# STM32F107xx register map
File version: 1.2
CPU: 
Registers are 32-bit, read-write, reset 0x0 unless marked. A register's access mark holds for its fields unless they carry their own. Offsets are from the block's base; [hi:lo] are bit positions; {n}, {i} and the like mark numbered series.

## CAN2 — Controller area network
Base 0x40006800
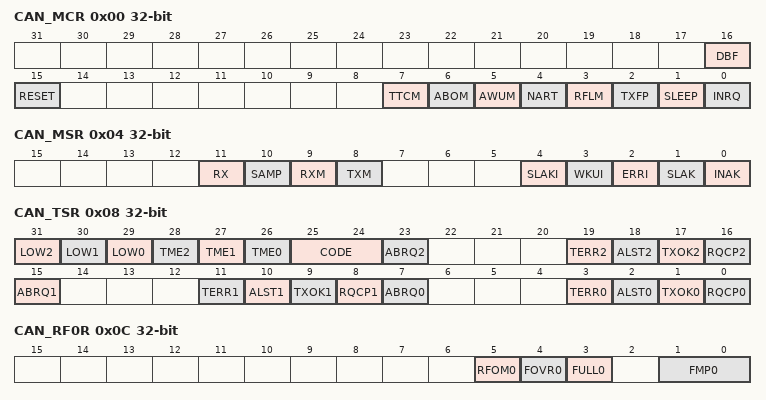
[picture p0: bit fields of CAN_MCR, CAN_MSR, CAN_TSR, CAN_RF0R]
0x00 CAN_MCR
  [16] DBF, [15] RESET, [7] TTCM, [6] ABOM, [5] AWUM, [4] NART, [3] RFLM, [2] TXFP, [1] SLEEP, [0] INRQ
0x04 CAN_MSR access per field
  [11] RX ro, [10] SAMP ro, [9] RXM ro, [8] TXM ro, [4] SLAKI rw, [3] WKUI rw, [2] ERRI rw, [1] SLAK ro, [0] INAK ro
0x08 CAN_TSR access per field
  [31] LOW2 ro — Lowest priority flag for mailbox 2
  [30] LOW1 ro — Lowest priority flag for mailbox 1
  [29] LOW0 ro — Lowest priority flag for mailbox 0
  [28] TME2 ro — Lowest priority flag for mailbox 2
  [27] TME1 ro — Lowest priority flag for mailbox 1
  [26] TME0 ro — Lowest priority flag for mailbox 0
  [25:24] CODE ro
  [23] ABRQ2 rw
  [19] TERR2 rw
  [18] ALST2 rw
  [17] TXOK2 rw
  [16] RQCP2 rw
  [15] ABRQ1 rw
  [11] TERR1 rw
  [10] ALST1 rw
  [9] TXOK1 rw
  [8] RQCP1 rw
  [7] ABRQ0 rw
  [3] TERR0 rw
  [2] ALST0 rw
  [1] TXOK0 rw
  [0] RQCP0 rw
0x0C CAN_RF0R access per field
  [5] RFOM0 rw, [4] FOVR0 rw, [3] FULL0 rw, [1:0] FMP0 ro
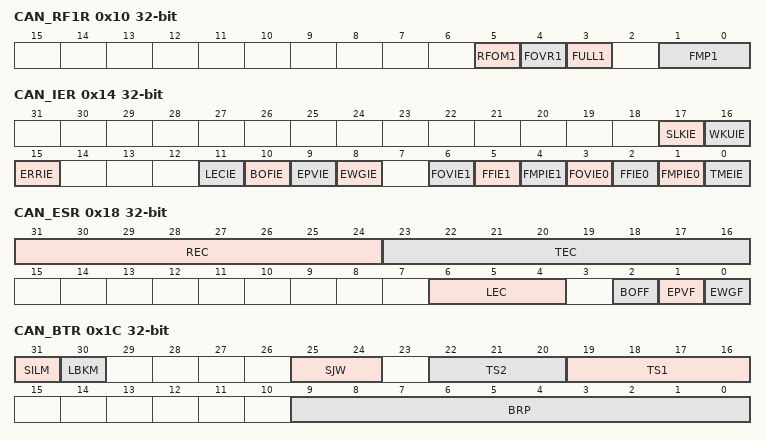
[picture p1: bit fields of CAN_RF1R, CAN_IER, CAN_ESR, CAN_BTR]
0x10 CAN_RF1R access per field
  [5] RFOM1 rw, [4] FOVR1 rw, [3] FULL1 rw, [1:0] FMP1 ro
0x14 CAN_IER
  [17] SLKIE, [16] WKUIE, [15] ERRIE, [11] LECIE, [10] BOFIE, [9] EPVIE, [8] EWGIE, [6] FOVIE1, [5] FFIE1, [4] FMPIE1, [3] FOVIE0, [2] FFIE0, [1] FMPIE0, [0] TMEIE
0x18 CAN_ESR access per field
  [31:24] REC ro, [23:16] TEC ro, [6:4] LEC rw, [2] BOFF ro, [1] EPVF ro, [0] EWGF ro
0x1C CAN_BTR
  [31] SILM, [30] LBKM, [25:24] SJW, [22:20] TS2, [19:16] TS1, [9:0] BRP
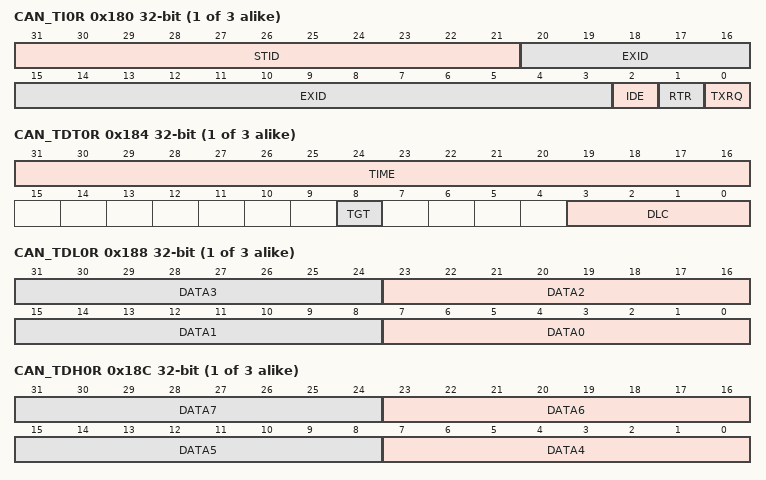
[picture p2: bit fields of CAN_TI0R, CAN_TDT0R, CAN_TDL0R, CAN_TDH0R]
{0x180+0x10*i} CAN_TI{i}R (i=0..2)
  [31:21] STID, [20:3] EXID, [2] IDE, [1] RTR, [0] TXRQ
{0x184+0x10*i} CAN_TDT{i}R (i=0..2)
  [31:16] TIME, [8] TGT, [3:0] DLC
{0x188+0x10*i} CAN_TDL{i}R (i=0..2)
  [8n+7:8n] DATA{n} (n=0..3)
{0x18C+0x10*i} CAN_TDH{i}R (i=0..2)
  [8n-25:8n-32] DATA{n} (n=4..7)
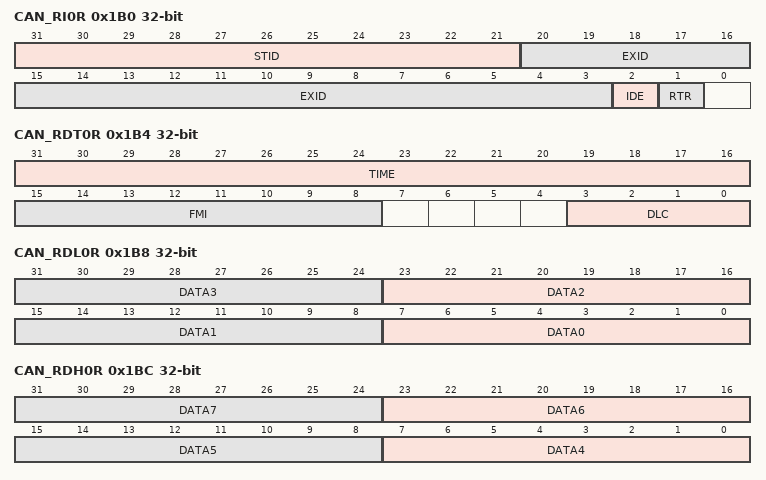
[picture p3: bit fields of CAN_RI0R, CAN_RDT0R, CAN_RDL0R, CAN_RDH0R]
0x1B0 CAN_RI0R ro
  [31:21] STID, [20:3] EXID, [2] IDE, [1] RTR
0x1B4 CAN_RDT0R ro
  [31:16] TIME, [15:8] FMI, [3:0] DLC
0x1B8 CAN_RDL0R ro
  [8n+7:8n] DATA{n} (n=0..3)
0x1BC CAN_RDH0R ro
  [8n-25:8n-32] DATA{n} (n=4..7)
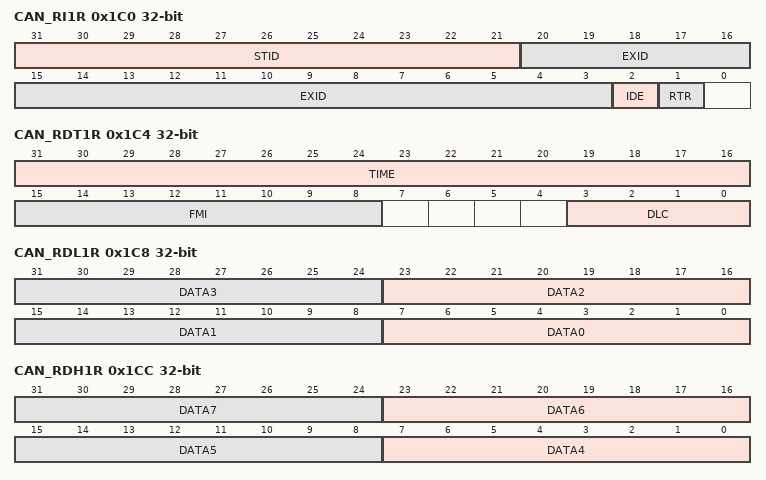
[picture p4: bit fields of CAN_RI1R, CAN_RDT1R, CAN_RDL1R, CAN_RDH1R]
0x1C0 CAN_RI1R ro
  [31:21] STID, [20:3] EXID, [2] IDE, [1] RTR
0x1C4 CAN_RDT1R ro
  [31:16] TIME, [15:8] FMI, [3:0] DLC
0x1C8 CAN_RDL1R ro
  [8n+7:8n] DATA{n} (n=0..3)
0x1CC CAN_RDH1R ro
  [8n-25:8n-32] DATA{n} (n=4..7)
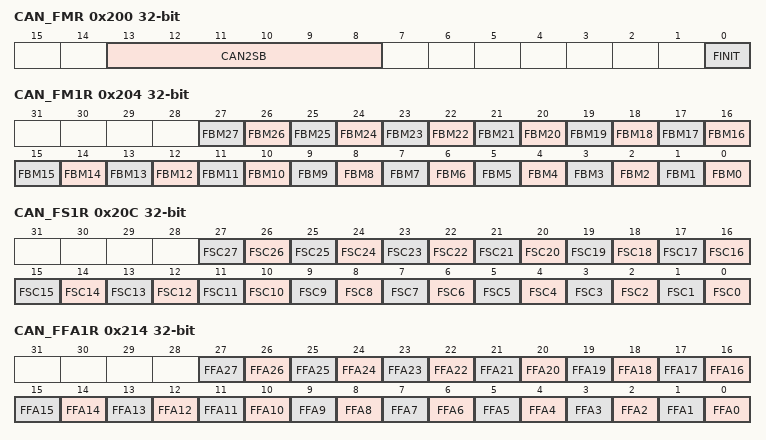
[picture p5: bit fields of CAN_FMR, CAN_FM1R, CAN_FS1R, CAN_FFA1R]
0x200 CAN_FMR
  [13:8] CAN2SB, [0] FINIT
0x204 CAN_FM1R
  [n] FBM{n} (n=0..27) — Filter mode
0x20C CAN_FS1R
  [n] FSC{n} (n=0..27) — Filter scale configuration
0x214 CAN_FFA1R
  [n] FFA{n} (n=0..27) — Filter FIFO assignment for filter {n}
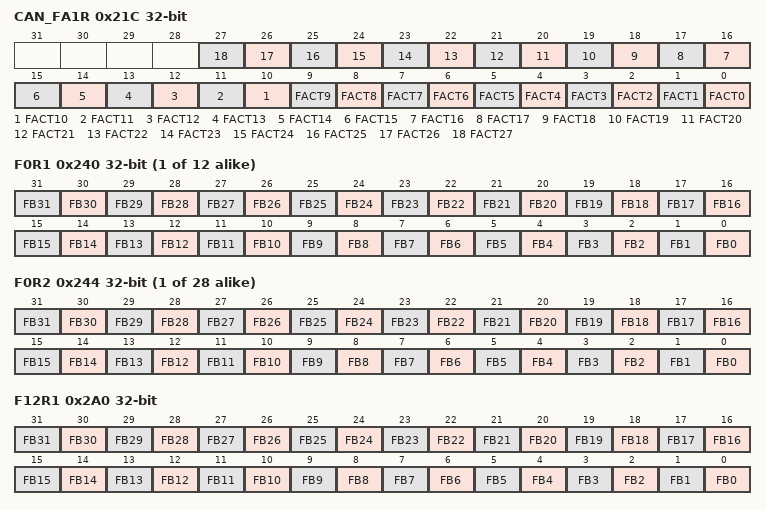
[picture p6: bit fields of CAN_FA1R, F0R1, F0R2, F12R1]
0x21C CAN_FA1R
  [n] FACT{n} (n=0..27) — Filter active
{0x240+8i} F{i}R1 (i=0..11) — Filter bank {i} register 1
  [n] FB{n} (n=0..31) — Filter bits
{0x244+8i} F{i}R2 (i=0..27) — Filter bank {i} register 2
  [n] FB{n} (n=0..31) — Filter bits
0x2A0 F12R1 — Filter bank 4 register 1
  [n] FB{n} (n=0..31) — Filter bits
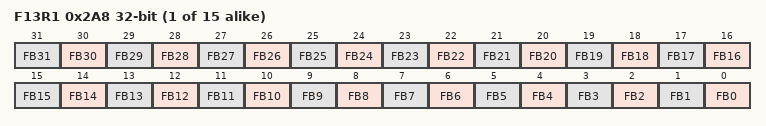
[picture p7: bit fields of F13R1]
{0x240+8i} F{i}R1 (i=13..27) — Filter bank {i} register 1
  [n] FB{n} (n=0..31) — Filter bits

## CAN1 — Controller area network
Base 0x40006400
Registers as CAN2; these are added or differ:
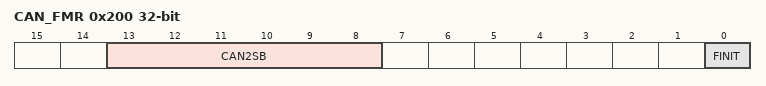
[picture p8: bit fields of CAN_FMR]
0x200 CAN_FMR
  [13:8] CAN2SB, [0] FINIT

## ETHERNET_MMC — Ethernet: MAC management counters
Base 0x40028100
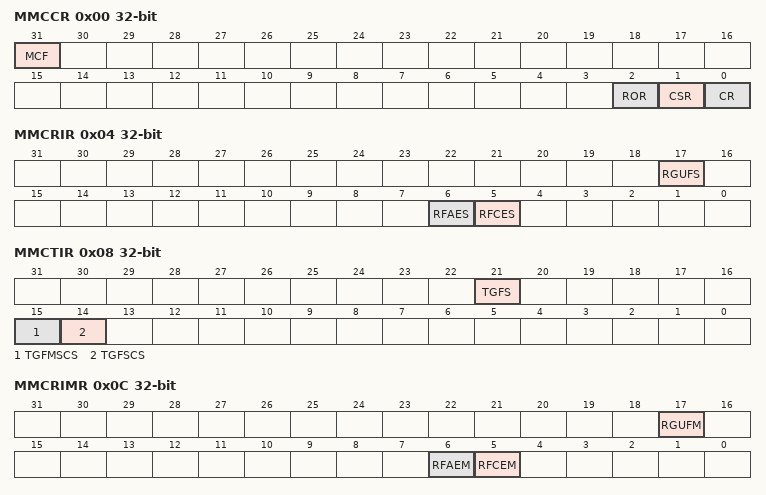
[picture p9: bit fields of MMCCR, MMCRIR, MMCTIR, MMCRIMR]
0x00 MMCCR — Ethernet MMC control register (ETH_MMCCR)
  [31] MCF — MMC counter freeze
  [2] ROR — Reset on read
  [1] CSR — Counter stop rollover
  [0] CR — Counter reset
0x04 MMCRIR — Ethernet MMC receive interrupt register (ETH_MMCRIR)
  [17] RGUFS — Received Good Unicast Frames Status
  [6] RFAES — Received frames alignment error status
  [5] RFCES — Received frames CRC error status
0x08 MMCTIR — Ethernet MMC transmit interrupt register (ETH_MMCTIR)
  [21] TGFS — Transmitted good frames status
  [15] TGFMSCS — Transmitted good frames more single collision status
  [14] TGFSCS — Transmitted good frames single collision status
0x0C MMCRIMR — Ethernet MMC receive interrupt mask register (ETH_MMCRIMR)
  [17] RGUFM — Received good unicast frames mask
  [6] RFAEM — Received frames alignment error mask
  [5] RFCEM — Received frame CRC error mask
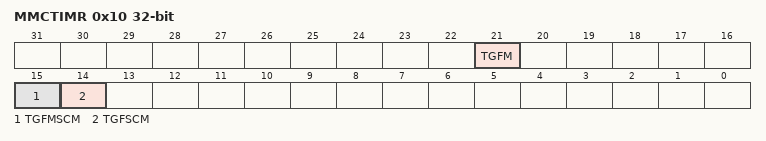
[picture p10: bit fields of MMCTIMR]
0x10 MMCTIMR — Ethernet MMC transmit interrupt mask register (ETH_MMCTIMR)
  [21] TGFM — Transmitted good frames mask
  [15] TGFMSCM — Transmitted good frames more single collision mask
  [14] TGFSCM — Transmitted good frames single collision mask
0x4C MMCTGFSCCR ro — Ethernet MMC transmitted good frames after a single collision counter
  [31:0] TGFSCC — Transmitted good frames after a single collision counter
0x50 MMCTGFMSCCR ro — Ethernet MMC transmitted good frames after more than a single collision
  [31:0] TGFMSCC — Transmitted good frames after more than a single collision counter
0x68 MMCTGFCR ro — Ethernet MMC transmitted good frames counter register
  [31:0] TGFC — Transmitted good frames counter
0x94 MMCRFCECR ro — Ethernet MMC received frames with CRC error counter register
  [31:0] RFCFC — Received frames with CRC error counter
0x98 MMCRFAECR ro — Ethernet MMC received frames with alignment error counter register
  [31:0] RFAEC — Received frames with alignment error counter
0xC4 MMCRGUFCR ro — MMC received good unicast frames counter register
  [31:0] RGUFC — Received good unicast frames counter
